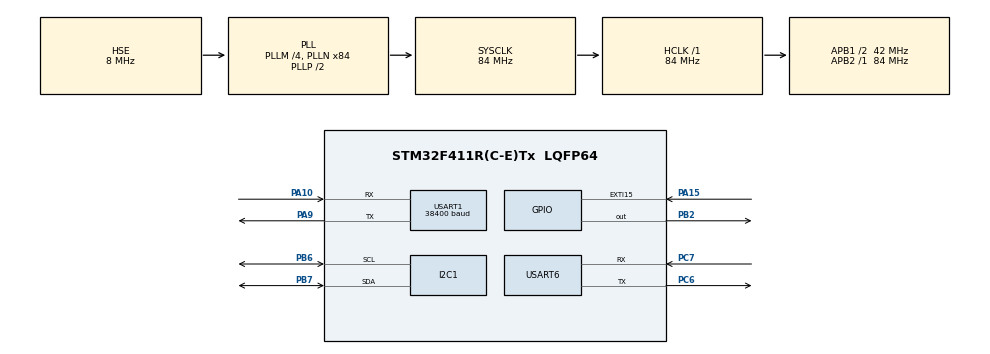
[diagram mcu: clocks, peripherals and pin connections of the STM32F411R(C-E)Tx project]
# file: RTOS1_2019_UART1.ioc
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FREERTOS.INCLUDE_vTaskDelayUntil=1
FREERTOS.Tasks01=defaultTask,0,128,StartDefaultTask,Default,NULL
FREERTOS.configUSE_COUNTING_SEMAPHORES=1
Mcu.Family=STM32F4
Mcu.Name=STM32F411R(C-E)Tx
Mcu.Package=LQFP64
NVIC.PriorityGroup=NVIC_PRIORITYGROUP_4
NVIC.TIM1_UP_TIM10_IRQn=true\:0\:0\:false\:false\:true\:false\:false\:true
NVIC.TimeBase=TIM1_UP_TIM10_IRQn
NVIC.TimeBaseIP=TIM1
PA10.GPIO_Mode=GPIO_MODE_AF_PP
PA10.GPIO_PuPd=GPIO_PULLUP
PA10.GPIO_Speed=GPIO_SPEED_FREQ_VERY_HIGH
PA10.Mode=Asynchronous
PA10.Signal=USART1_RX
PA13.Mode=Serial_Wire
PA13.Signal=SYS_JTMS-SWDIO
PA14.Mode=Serial_Wire
PA14.Signal=SYS_JTCK-SWCLK
PA15.GPIO_ModeDefaultEXTI=GPIO_MODE_IT_RISING
PA15.GPIO_PuPd=GPIO_NOPULL
PA15.Signal=GPXTI15
PA9.GPIO_Mode=GPIO_MODE_AF_PP
PA9.GPIO_PuPd=GPIO_PULLUP
PA9.GPIO_Speed=GPIO_SPEED_FREQ_VERY_HIGH
PA9.Mode=Asynchronous
PA9.Signal=USART1_TX
PB2.GPIO_ModeDefaultOutputPP=GPIO_MODE_OUTPUT_PP
PB2.GPIO_PuPd=GPIO_NOPULL
PB2.GPIO_Speed=GPIO_SPEED_FREQ_LOW
PB2.PinState=GPIO_PIN_RESET
PB2.Signal=GPIO_Output
PB6.Mode=I2C
PB6.Signal=I2C1_SCL
PB7.Mode=I2C
PB7.Signal=I2C1_SDA
PC6.Mode=Asynchronous
PC6.Signal=USART6_TX
PC7.Mode=Asynchronous
PC7.Signal=USART6_RX
PH0\ -\ OSC_IN.Mode=HSE-External-Oscillator
PH0\ -\ OSC_IN.Signal=RCC_OSC_IN
PH1\ -\ OSC_OUT.Mode=HSE-External-Oscillator
PH1\ -\ OSC_OUT.Signal=RCC_OSC_OUT
ProjectManager.HeapSize=0x200
ProjectManager.StackSize=0x400
ProjectManager.TargetToolchain=SW4STM32
RCC.48MHZClocksFreq_Value=42000000
RCC.AHBFreq_Value=84000000
RCC.APB1CLKDivider=RCC_HCLK_DIV2
RCC.APB1Freq_Value=42000000
RCC.APB1TimFreq_Value=84000000
RCC.APB2Freq_Value=84000000
RCC.APB2TimFreq_Value=84000000
RCC.CortexFreq_Value=84000000
RCC.HCLKFreq_Value=84000000
RCC.HSE_VALUE=8000000
RCC.HSI_VALUE=16000000
RCC.LSE_VALUE=32768
RCC.PLLM=4
RCC.PLLN=84
RCC.PLLSourceVirtual=RCC_PLLSOURCE_HSE
RCC.SYSCLKFreq_VALUE=84000000
RCC.SYSCLKSource=RCC_SYSCLKSOURCE_PLLCLK
RCC.VCOOutputFreq_Value=168000000
USART1.BaudRate=38400
USART1.VirtualMode=VM_ASYNC
USART6.VirtualMode=VM_ASYNC
VP_FREERTOS_VS_CMSIS_V1.Mode=CMSIS_V1
VP_SYS_VS_tim1.Mode=TIM1
board=test_01_LED

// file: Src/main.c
/* USER CODE BEGIN Header */
/**
  ******************************************************************************
  * @file           : main.c
  * @brief          : Main program body
  ******************************************************************************
  * @attention
  *
  * <h2><center>&copy; Copyright (c) 2019 STMicroelectronics.
  * All rights reserved.</center></h2>
  *
  * This software component is licensed by ST under Ultimate Liberty license
  * SLA0044, the "License"; You may not use this file except in compliance with
  * the License. You may obtain a copy of the License at:
  *                             www.st.com/SLA0044
  *
  ******************************************************************************
  */
/* USER CODE END Header */

#include <stdio.h>
#include "main.h"
#include "cmsis_os.h"
#include "i2c.h"
#include "usart.h"
#include "gpio.h"

/* USER CODE BEGIN PD */
TaskHandle_t xTaskHandle1 = NULL;
/* USER CODE END PD */

void SystemClock_Config(void);
void MX_FREERTOS_Init(void);
// 3b. Task Functions prototypes:
void vTask1_handler(void *params);

int main(void)
{

  /* MCU Configuration--------------------------------------------------------*/

  /* Reset of all peripherals, Initializes the Flash interface and the Systick. */
  HAL_Init();

  /* Configure the system clock */
  SystemClock_Config();

  /* Initialize all configured peripherals */
  MX_GPIO_Init();
  MX_I2C1_Init();
  MX_USART6_UART_Init();
  MX_USART1_UART_Init();
  /* USER CODE BEGIN 2 */
  uint8_t data[40];
   //uint8_t rxdata = 0;
   //uint8_t PCA_Out_value = 0x10;

     sprintf((char *)data,"CESE2\n\r");
     HAL_UART_Transmit(&huart6, data, 10, 10);
     HAL_Delay(100);
   // Added 10.4.2019 Transmit @38400 thru UART1
     sprintf((char *)data,"UART1\n\r");
     HAL_UART_Transmit(&huart1, data, 10, 10);
     HAL_Delay(100);
  /* USER CODE END 2 */

  /* Call init function for freertos objects (in freertos.c) */
  MX_FREERTOS_Init();
  // 3. Create 2 tasks..
  xTaskCreate(vTask1_handler,
  				"Task-1",  // char
  				configMINIMAL_STACK_SIZE,
  				NULL,
  				2,   // Max is 5 in FRTCFG.h..
  				&xTaskHandle1);

  /* Start scheduler */
  osKernelStart();

  /* We should never get here as control is now taken by the scheduler */

  /* Infinite loop */
  while (1)
  {

  }
}

void SystemClock_Config(void)
{
  RCC_OscInitTypeDef RCC_OscInitStruct = {0};
  RCC_ClkInitTypeDef RCC_ClkInitStruct = {0};

  /** Configure the main internal regulator output voltage
  */
  __HAL_RCC_PWR_CLK_ENABLE();
  __HAL_PWR_VOLTAGESCALING_CONFIG(PWR_REGULATOR_VOLTAGE_SCALE1);
  /** Initializes the CPU, AHB and APB busses clocks
  */
  RCC_OscInitStruct.OscillatorType = RCC_OSCILLATORTYPE_HSE;
  RCC_OscInitStruct.HSEState = RCC_HSE_ON;
  RCC_OscInitStruct.PLL.PLLState = RCC_PLL_ON;
  RCC_OscInitStruct.PLL.PLLSource = RCC_PLLSOURCE_HSE;
  RCC_OscInitStruct.PLL.PLLM = 4;
  RCC_OscInitStruct.PLL.PLLN = 84;
  RCC_OscInitStruct.PLL.PLLP = RCC_PLLP_DIV2;
  RCC_OscInitStruct.PLL.PLLQ = 4;
  if (HAL_RCC_OscConfig(&RCC_OscInitStruct) != HAL_OK)
  {
    Error_Handler();
  }
  /** Initializes the CPU, AHB and APB busses clocks
  */
  RCC_ClkInitStruct.ClockType = RCC_CLOCKTYPE_HCLK|RCC_CLOCKTYPE_SYSCLK
                              |RCC_CLOCKTYPE_PCLK1|RCC_CLOCKTYPE_PCLK2;
  RCC_ClkInitStruct.SYSCLKSource = RCC_SYSCLKSOURCE_PLLCLK;
  RCC_ClkInitStruct.AHBCLKDivider = RCC_SYSCLK_DIV1;
  RCC_ClkInitStruct.APB1CLKDivider = RCC_HCLK_DIV2;
  RCC_ClkInitStruct.APB2CLKDivider = RCC_HCLK_DIV1;

  if (HAL_RCC_ClockConfig(&RCC_ClkInitStruct, FLASH_LATENCY_2) != HAL_OK)
  {
    Error_Handler();
  }
}

void HAL_TIM_PeriodElapsedCallback(TIM_HandleTypeDef *htim)
{
  if (htim->Instance == TIM1) {
    HAL_IncTick();
  }
}

void vTask1_handler(void *params)
{
	uint8_t data1[40];
	while(1){
	     sprintf((char *)data1,"U1b\n\r");
	     HAL_UART_Transmit(&huart1, data1, 10, 10);
	     vTaskDelay(500/portTICK_RATE_MS);
	}
}

void Error_Handler(void)
{
}

/************************ (C) COPYRIGHT STMicroelectronics *****END OF FILE****/
